VERSION "HIPBNYYYYYYYYYYYYYYYYYYYYYYYYYYYYYYYYYYYYY/4/%%%/4/'%**4YYY///"

NS_ :

BS_:

BU_:

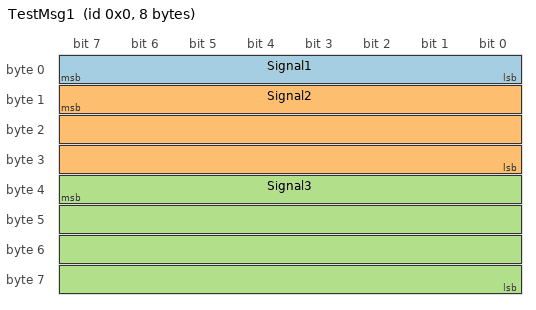
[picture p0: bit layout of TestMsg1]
BO_ 0 TestMsg1: 8 Vector__XXX
 SG_ Signal1 : 7|8@0- (1,0) [0|0] "" Vector__XXX
 SG_ Signal2 : 15|24@0- (1,0) [0|0] "" Vector__XXX
 SG_ Signal3 : 39|32@0- (1,0) [0|0] "" Vector__XXX

BO_ 1 TestMsg2: 8 Vector__XXX
 SG_ GPS_validity_status : 7|8@0- (1,0) [0|0] "" Vector__XXX
